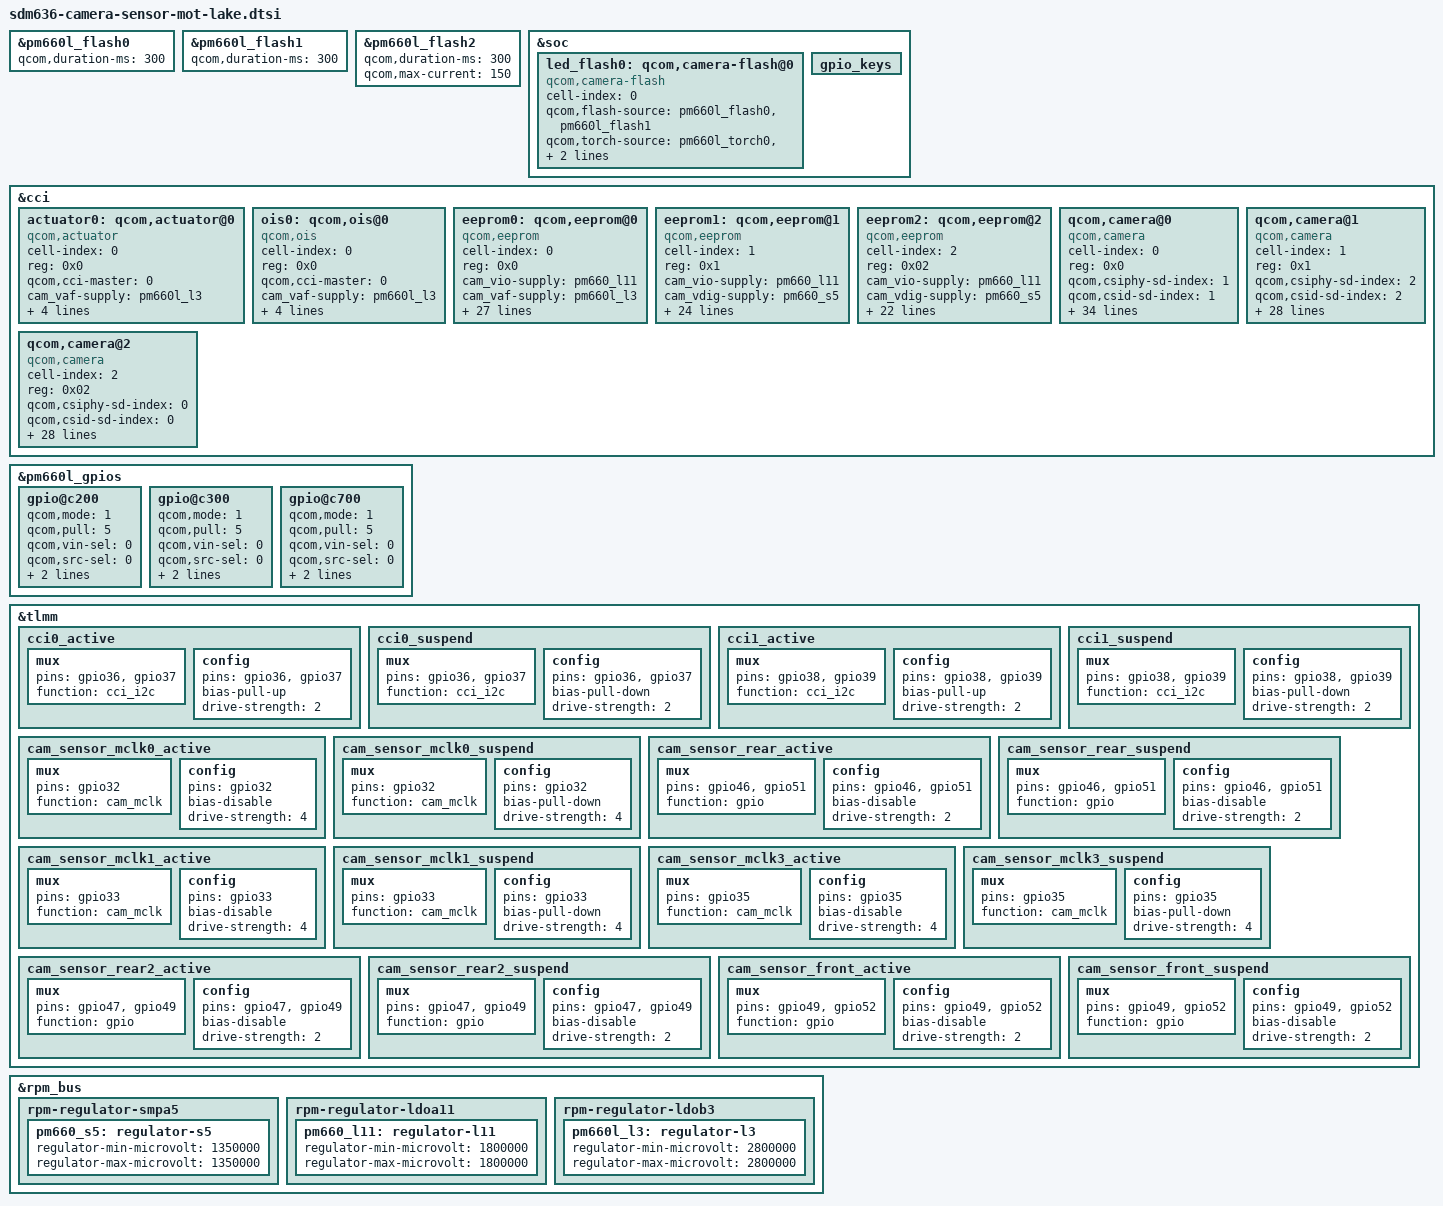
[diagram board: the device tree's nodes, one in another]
/*
 * Copyright (c) 2018, The Linux Foundation. All rights reserved.
 *
 * This program is free software; you can redistribute it and/or modify
 * it under the terms of the GNU General Public License version 2 and
 * only version 2 as published by the Free Software Foundation.
 *
 * This program is distributed in the hope that it will be useful,
 * but WITHOUT ANY WARRANTY; without even the implied warranty of
 * MERCHANTABILITY or FITNESS FOR A PARTICULAR PURPOSE.  See the
 * GNU General Public License for more details.
 */

&pm660l_flash0 {
	qcom,duration-ms = <300>;
};

&pm660l_flash1 {
	qcom,duration-ms = <300>;
};

&pm660l_flash2 {
	qcom,duration-ms = <300>;
	qcom,max-current = <150>;
};

&soc {
	led_flash0: qcom,camera-flash@0 {
		cell-index = <0>;
		compatible = "qcom,camera-flash";
		qcom,flash-source = <&pm660l_flash0 &pm660l_flash1>;
		qcom,torch-source = <&pm660l_torch0 &pm660l_torch1>;
		qcom,switch-source = <&pm660l_switch0>;
		status = "ok";
	};

	gpio_keys {
		/delete-node/camera_focus;
		/delete-node/camera_snapshot;
	};
};

&cci {
	actuator0: qcom,actuator@0 {
		cell-index = <0>;
		reg = <0x0>;
		compatible = "qcom,actuator";
		qcom,cci-master = <0>;
		cam_vaf-supply = <&pm660l_l3>;
		qcom,cam-vreg-name = "cam_vaf";
		qcom,cam-vreg-min-voltage = <2800000>;
		qcom,cam-vreg-max-voltage = <2800000>;
		qcom,cam-vreg-op-mode = <80000>;
	};

	ois0: qcom,ois@0 {
		cell-index = <0>;
		reg = <0x0>;
		compatible = "qcom,ois";
		qcom,cci-master = <0>;
		cam_vaf-supply = <&pm660l_l3>;
		qcom,cam-vreg-name = "cam_vaf";
		qcom,cam-vreg-min-voltage = <2800000>;
		qcom,cam-vreg-max-voltage = <2800000>;
		qcom,cam-vreg-op-mode = <100000>;
	};

	eeprom0: qcom,eeprom@0 {
		cell-index = <0>;
		compatible = "qcom,eeprom";
		reg = <0x0>;
		cam_vio-supply = <&pm660_l11>;
		cam_vaf-supply = <&pm660l_l3>;
		cam_vdig-supply = <&pm660_s5>;
		qcom,cam-vreg-name = "cam_vio", "cam_vaf", "cam_vdig";
		qcom,cam-vreg-min-voltage = <1800000 2800000 1350000>;
		qcom,cam-vreg-max-voltage = <1800000 2800000 1350000>;
		qcom,cam-vreg-op-mode = <105000 80000 105000>;
		qcom,gpio-no-mux = <0>;
		pinctrl-names = "cam_default", "cam_suspend";
		pinctrl-0 = <&cam_sensor_mclk0_active
				 &cam_sensor_rear_active>;
		pinctrl-1 = <&cam_sensor_mclk0_suspend
				 &cam_sensor_rear_suspend>;
		gpios = <&tlmm 32 0>,
			<&tlmm 46 0>,
			<&pm660l_gpios 4 0>,
			<&tlmm 51 0>;
		qcom,gpio-reset = <1>;
		qcom,gpio-vdig = <2>;
		qcom,gpio-vana = <3>;
		qcom,gpio-req-tbl-num = <0 1 2 3>;
		qcom,gpio-req-tbl-flags = <1 0 0 0>;
		qcom,gpio-req-tbl-label = "CAMIF_MCLK0",
					"CAM_RESET0",
					"CAM_VDIG0",
					"CAM_VANA0";
		qcom,sensor-position = <0>;
		qcom,sensor-mode = <0>;
		qcom,cci-master = <0>;
		status = "ok";
		clocks = <&clock_mmss MCLK0_CLK_SRC>,
				<&clock_mmss MMSS_CAMSS_MCLK0_CLK>;
		clock-names = "cam_src_clk", "cam_clk";
		qcom,clock-rates = <24000000 0>;
	};

	eeprom1: qcom,eeprom@1 {
		cell-index = <1>;
		compatible = "qcom,eeprom";
		reg = <0x1>;
		cam_vio-supply = <&pm660_l11>;
		cam_vdig-supply = <&pm660_s5>;
		qcom,cam-vreg-name = "cam_vio", "cam_vdig";
		qcom,cam-vreg-min-voltage = <1800000 1350000>;
		qcom,cam-vreg-max-voltage = <1800000 1350000>;
		qcom,cam-vreg-op-mode = <105000 105000>;
		qcom,gpio-no-mux = <0>;
		pinctrl-names = "cam_default", "cam_suspend";
		pinctrl-0 = <&cam_sensor_mclk1_active
				 &cam_sensor_front_active>;
		pinctrl-1 = <&cam_sensor_mclk1_suspend
				 &cam_sensor_front_suspend>;
		gpios = <&tlmm 33 0>,
			<&tlmm 52 0>,
			<&pm660l_gpios 8 0>,
			<&tlmm 49 0>;
		qcom,gpio-reset = <1>;
		qcom,gpio-vdig = <2>;
		qcom,gpio-vana = <3>;
		qcom,gpio-req-tbl-num = <0 1 2 3>;
		qcom,gpio-req-tbl-flags = <1 0 0 0>;
		qcom,gpio-req-tbl-label = "CAMIF_MCLK1",
					"CAM_RESET1",
					"CAM_VDIG1",
					"CAM_VANA1";
		qcom,sensor-position = <1>;
		qcom,sensor-mode = <0>;
		qcom,cci-master = <1>;
		status = "ok";
		clocks = <&clock_mmss MCLK1_CLK_SRC>,
			<&clock_mmss MMSS_CAMSS_MCLK1_CLK>;
		clock-names = "cam_src_clk", "cam_clk";
		qcom,clock-rates = <24000000 0>;
	};

	eeprom2: qcom,eeprom@2 {
		cell-index = <2>;
		compatible = "qcom,eeprom";
		reg = <0x02>;
		cam_vio-supply = <&pm660_l11>;
		cam_vdig-supply = <&pm660_s5>;
		qcom,cam-vreg-name = "cam_vio", "cam_vdig";
		qcom,cam-vreg-min-voltage = <1800000 1350000>;
		qcom,cam-vreg-max-voltage = <1800000 1350000>;
		qcom,cam-vreg-op-mode = <105000 105000>;
		qcom,gpio-no-mux = <0>;
		pinctrl-names = "cam_default", "cam_suspend";
		pinctrl-0 = <&cam_sensor_mclk3_active
				 &cam_sensor_rear2_active>;
		pinctrl-1 = <&cam_sensor_mclk3_suspend
				 &cam_sensor_rear2_suspend>;
		gpios = <&tlmm 35 0>,
			<&tlmm 47 0>,
			<&pm660l_gpios 8 0>,
			<&tlmm 49 0>;
		qcom,gpio-reset = <1>;
		qcom,gpio-vdig = <2>;
		qcom,gpio-vana = <3>;
		qcom,gpio-req-tbl-num = <0 1 2 3>;
		qcom,gpio-req-tbl-flags = <1 0 0 0>;
		qcom,gpio-req-tbl-label = "CAMIF_MCLK2",
					"CAM_RESET2",
					"CAM_VDIG2",
					"CAM_VANA2";
		qcom,cci-master = <0>;
		status = "ok";
		clocks = <&clock_mmss MCLK3_CLK_SRC>,
			<&clock_mmss MMSS_CAMSS_MCLK3_CLK>;
		clock-names = "cam_src_clk", "cam_clk";
		qcom,clock-rates = <24000000 0>;
	};

	/*IMX519*/
	qcom,camera@0 {
		cell-index = <0>;
		compatible = "qcom,camera";
		reg = <0x0>;
		qcom,csiphy-sd-index = <1>;
		qcom,csid-sd-index = <1>;
		qcom,mount-angle = <90>;
		qcom,led-flash-src = <&led_flash0>;
		qcom,actuator-src = <&actuator0>;
		qcom,ois-src = <&ois0>;
		qcom,eeprom-src = <&eeprom0>;
		cam_vio-supply = <&pm660_l11>;
		cam_vaf-supply = <&pm660l_l3>;
		cam_vdig-supply = <&pm660_s5>;
		qcom,cam-vreg-name = "cam_vio", "cam_vaf", "cam_vdig";
		qcom,cam-vreg-min-voltage = <1800000 2800000 1350000>;
		qcom,cam-vreg-max-voltage = <1800000 2800000 1350000>;
		qcom,cam-vreg-op-mode = <105000 80000 105000>;
		qcom,gpio-no-mux = <0>;
		pinctrl-names = "cam_default", "cam_suspend";
		pinctrl-0 = <&cam_sensor_mclk0_active
				 &cam_sensor_rear_active>;
		pinctrl-1 = <&cam_sensor_mclk0_suspend
				 &cam_sensor_rear_suspend>;
		gpios = <&tlmm 32 0>,
			<&tlmm 46 0>,
			<&pm660l_gpios 4 0>,
			<&tlmm 51 0>;
		qcom,gpio-reset = <1>;
		qcom,gpio-vdig = <2>;
		qcom,gpio-vana = <3>;
		qcom,gpio-req-tbl-num = <0 1 2 3>;
		qcom,gpio-req-tbl-flags = <1 0 0 0>;
		qcom,gpio-req-tbl-label = "CAMIF_MCLK0",
					"CAM_RESET0",
					"CAM_VDIG0",
					"CAM_VANA0";
		qcom,sensor-position = <0>;
		qcom,sensor-mode = <0>;
		qcom,cci-master = <0>;
		status = "ok";
		clocks = <&clock_mmss MCLK0_CLK_SRC>,
				<&clock_mmss MMSS_CAMSS_MCLK0_CLK>;
		clock-names = "cam_src_clk", "cam_clk";
		qcom,clock-rates = <24000000 0>;
	};
	/*OV12A10*/
	qcom,camera@1 {
		cell-index = <1>;
		compatible = "qcom,camera";
		reg = <0x1>;
		qcom,csiphy-sd-index = <2>;
		qcom,csid-sd-index = <2>;
		qcom,mount-angle = <270>;
		qcom,eeprom-src = <&eeprom1>;
		cam_vio-supply = <&pm660_l11>;
		cam_vdig-supply = <&pm660_s5>;
		qcom,cam-vreg-name = "cam_vio", "cam_vdig";
		qcom,cam-vreg-min-voltage = <1800000 1350000>;
		qcom,cam-vreg-max-voltage = <1800000 1350000>;
		qcom,cam-vreg-op-mode = <105000 105000>;
		qcom,gpio-no-mux = <0>;
		pinctrl-names = "cam_default", "cam_suspend";
		pinctrl-0 = <&cam_sensor_mclk1_active
				 &cam_sensor_front_active>;
		pinctrl-1 = <&cam_sensor_mclk1_suspend
				 &cam_sensor_front_suspend>;
		gpios = <&tlmm 33 0>,
			<&tlmm 52 0>,
			<&pm660l_gpios 8 0>,
			<&tlmm 49 0>;
		qcom,gpio-reset = <1>;
		qcom,gpio-vdig = <2>;
		qcom,gpio-vana = <3>;
		qcom,gpio-req-tbl-num = <0 1 2 3>;
		qcom,gpio-req-tbl-flags = <1 0 0 0>;
		qcom,gpio-req-tbl-label = "CAMIF_MCLK1",
					"CAM_RESET1",
					"CAM_VDIG1",
					"CAM_VANA1";
		qcom,sensor-position = <1>;
		qcom,sensor-mode = <0>;
		qcom,cci-master = <1>;
		status = "ok";
		clocks = <&clock_mmss MCLK1_CLK_SRC>,
			<&clock_mmss MMSS_CAMSS_MCLK1_CLK>;
		clock-names = "cam_src_clk", "cam_clk";
		qcom,clock-rates = <24000000 0>;
	};

	qcom,camera@2 {
		cell-index = <2>;
		compatible = "qcom,camera";
		reg = <0x02>;
		qcom,csiphy-sd-index = <0>;
		qcom,csid-sd-index = <0>;
		qcom,mount-angle = <90>;
		qcom,eeprom-src = <&eeprom2>;
		cam_vio-supply = <&pm660_l11>;
		cam_vdig-supply = <&pm660_s5>;
		qcom,cam-vreg-name = "cam_vio", "cam_vdig";
		qcom,cam-vreg-min-voltage = <1800000 1350000>;
		qcom,cam-vreg-max-voltage = <1800000 1350000>;
		qcom,cam-vreg-op-mode = <105000 105000>;
		qcom,gpio-no-mux = <0>;
		pinctrl-names = "cam_default", "cam_suspend";
		pinctrl-0 = <&cam_sensor_mclk3_active
				 &cam_sensor_rear2_active>;
		pinctrl-1 = <&cam_sensor_mclk3_suspend
				 &cam_sensor_rear2_suspend>;
		gpios = <&tlmm 35 0>,
			<&tlmm 47 0>,
			<&pm660l_gpios 8 0>,
			<&tlmm 49 0>;
		qcom,gpio-reset = <1>;
		qcom,gpio-vdig = <2>;
		qcom,gpio-vana = <3>;
		qcom,gpio-req-tbl-num = <0 1 2 3>;
		qcom,gpio-req-tbl-flags = <1 0 0 0>;
		qcom,gpio-req-tbl-label = "CAMIF_MCLK2",
					"CAM_RESET2",
					"CAM_VDIG2",
					"CAM_VANA2";
		qcom,sensor-position = <0>;
		qcom,sensor-mode = <0>;
		qcom,cci-master = <0>;
		status = "ok";
		clocks = <&clock_mmss MCLK3_CLK_SRC>,
			<&clock_mmss MMSS_CAMSS_MCLK3_CLK>;
		clock-names = "cam_src_clk", "cam_clk";
		qcom,clock-rates = <24000000 0>;
	};
};

&pm660l_gpios {
	gpio@c200 { /* GPIO3 -CAMERA SENSOR 1 VDIG*/
		qcom,mode = <1>;                /* Output */
		qcom,pull = <5>;                /* No Pull */
		qcom,vin-sel = <0>;             /* VIN1 GPIO_LV */
		qcom,src-sel = <0>;             /* GPIO */
		qcom,invert = <0>;              /* Invert */
		qcom,master-en = <1>;           /* Enable GPIO */
		status = "ok";
	};
	gpio@c300 { /* GPIO4 -CAMERA SENSOR 0 VDIG*/
		qcom,mode = <1>;                /* Output */
		qcom,pull = <5>;                /* No Pull */
		qcom,vin-sel = <0>;             /* VIN1 GPIO_LV */
		qcom,src-sel = <0>;             /* GPIO */
		qcom,invert = <0>;              /* Invert */
		qcom,master-en = <1>;           /* Enable GPIO */
		status = "ok";
	};
	gpio@c700 { /* GPIO8 -CAMERA SENSOR 0 VDIG*/
		qcom,mode = <1>;                /* Output */
		qcom,pull = <5>;                /* No Pull */
		qcom,vin-sel = <0>;             /* VIN1 GPIO_LV */
		qcom,src-sel = <0>;             /* GPIO */
		qcom,invert = <0>;              /* Invert */
		qcom,master-en = <1>;           /* Enable GPIO */
		status = "ok";
	};
};

&tlmm {
	cci0_active: cci0_active {
		mux {
			/* CLK, DATA */
			pins = "gpio36","gpio37"; // Only 2
			function = "cci_i2c";
		};

		config {
			pins = "gpio36","gpio37";
			bias-pull-up; /* PULL UP*/
			drive-strength = <2>; /* 2 MA */
		};
	};

	cci0_suspend: cci0_suspend {
		mux {
			/* CLK, DATA */
			pins = "gpio36","gpio37";
			function = "cci_i2c";
		};

		config {
			pins = "gpio36","gpio37";
			bias-pull-down; /* PULL DOWN */
			drive-strength = <2>; /* 2 MA */
		};
	};

	cci1_active: cci1_active {
		mux {
			/* CLK, DATA */
			pins = "gpio38","gpio39";
			function = "cci_i2c";
		};

		config {
			pins = "gpio38","gpio39";
			bias-pull-up; /* PULL UP*/
			drive-strength = <2>; /* 2 MA */
		};
	};

	cci1_suspend: cci1_suspend {
		mux {
			/* CLK, DATA */
			pins = "gpio38","gpio39";
			function = "cci_i2c";
		};


		config {
			pins = "gpio38","gpio39";
			bias-pull-down; /* PULL DOWN */
			drive-strength = <2>; /* 2 MA */
		};
	};

	cam_sensor_mclk0_active: cam_sensor_mclk0_active {
		/* MCLK0 */
		mux {
			/* CLK, DATA */
			pins = "gpio32";
			function = "cam_mclk";
		};

		config {
			pins = "gpio32";
			bias-disable; /* No PULL */
			drive-strength = <4>; /* 4 MA */
		};
	};

	cam_sensor_mclk0_suspend: cam_sensor_mclk0_suspend {
		/* MCLK0 */
		mux {
			/* CLK, DATA */
			pins = "gpio32";
			function = "cam_mclk";
		};

		config {
			pins = "gpio32";
			bias-pull-down; /* PULL DOWN */
			drive-strength = <4>; /* 4 MA */
		};
	};

	cam_sensor_rear_active: cam_sensor_rear_active {
		/* RESET, VANA */
		mux {
			pins = "gpio46","gpio51";
			function = "gpio";
		};

		config {
			pins = "gpio46","gpio51";
			bias-disable; /* No PULL */
			drive-strength = <2>; /* 2 MA */
		};
	};

	cam_sensor_rear_suspend: cam_sensor_rear_suspend {
		/* RESET, VANA */
		mux {
			pins = "gpio46","gpio51";
			function = "gpio";
		};

		config {
			pins = "gpio46","gpio51";
			bias-disable; /* No PULL */
			drive-strength = <2>; /* 2 MA */
		};
	};

	cam_sensor_mclk1_active: cam_sensor_mclk1_active {
		/* MCLK1 */
		mux {
			/* CLK, DATA */
			pins = "gpio33";
			function = "cam_mclk";
		};

		config {
			pins = "gpio33";
			bias-disable; /* No PULL */
			drive-strength = <4>; /* 4 MA */
		};
	};

	cam_sensor_mclk1_suspend: cam_sensor_mclk1_suspend {
		/* MCLK1 */
		mux {
			/* CLK, DATA */
			pins = "gpio33";
			function = "cam_mclk";
		};

		config {
			pins = "gpio33";
			bias-pull-down; /* PULL DOWN */
			drive-strength = <4>; /* 4 MA */
		};
	};

	cam_sensor_mclk3_active: cam_sensor_mclk3_active {
		/* MCLK1 */
		mux {
			/* CLK, DATA */
			pins = "gpio35";
			function = "cam_mclk";
		};

		config {
			pins = "gpio35";
			bias-disable; /* No PULL */
			drive-strength = <4>; /* 4 MA */
		};
	};

	cam_sensor_mclk3_suspend: cam_sensor_mclk3_suspend {
		/* MCLK1 */
		mux {
			/* CLK, DATA */
			pins = "gpio35";
		function = "cam_mclk";
		};

		config {
			pins = "gpio35";
			bias-pull-down; /* PULL DOWN */
			drive-strength = <4>; /* 4 MA */
		};
	};

	cam_sensor_rear2_active: cam_sensor_rear2_active {
		/* RESET, STANDBY */
		mux {
			pins = "gpio47","gpio49";
			function = "gpio";
		};

		config {
			pins = "gpio47","gpio49";
			bias-disable; /* No PULL */
			drive-strength = <2>; /* 2 MA */
		};
	};

	cam_sensor_rear2_suspend: cam_sensor_rear2_suspend {
		/* RESET, STANDBY */
		mux {
			pins = "gpio47","gpio49";
			function = "gpio";
		};
		config {
			pins = "gpio47","gpio49";
			bias-disable; /* No PULL */
			drive-strength = <2>; /* 2 MA */
		};
	};

	cam_sensor_front_active: cam_sensor_front_active {
		/* RESET  VANA*/
		mux {
			pins = "gpio49","gpio52";
			function = "gpio";
		};

		config {
			pins = "gpio49","gpio52";
			bias-disable; /* No PULL */
			drive-strength = <2>; /* 2 MA */
		};
	};

	cam_sensor_front_suspend: cam_sensor_front_suspend {
		/* RESET */
		mux {
			pins = "gpio49","gpio52";
			function = "gpio";
		};

		config {
			pins = "gpio49","gpio52";
			bias-disable; /* No PULL */
			drive-strength = <2>; /* 2 MA */
		};
	};
};

&rpm_bus {
	rpm-regulator-smpa5 {
		status = "okay";
		pm660_s5: regulator-s5 {
			regulator-min-microvolt = <1350000>;
			regulator-max-microvolt = <1350000>;
			status = "okay";
		};
	};

	rpm-regulator-ldoa11 {
		status = "okay";
		pm660_l11: regulator-l11 {
			regulator-min-microvolt = <1800000>;
			regulator-max-microvolt = <1800000>;
			status = "okay";
		};
	};

	rpm-regulator-ldob3 {
		status = "okay";
		pm660l_l3: regulator-l3 {
			regulator-min-microvolt = <2800000>;
			regulator-max-microvolt = <2800000>;
			status = "okay";
		};
	};
};
